# ATSAMG55J register map
Vendor: Microchip Technology; Series: SAMG55; File version: 0
CPU: CM4 r0p1, little endian, MPU, FPU, 4 interrupt priority bits
Registers are 32-bit, read-write, reset 0x0 unless marked. A register's access mark holds for its fields unless they carry their own. Offsets are from the block's base; [hi:lo] are bit positions; {n}, {i} and the like mark numbered series.

## RSTC — Reset Controller
Base 0x400E1400; register names take the prefix RSTC_
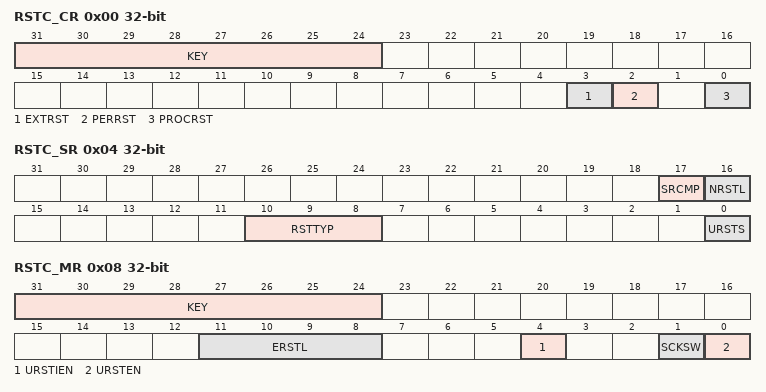
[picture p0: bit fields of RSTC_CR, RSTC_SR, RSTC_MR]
0x00 RSTC_CR wo — Control Register
  [31:24] KEY — System Reset Key
    165=PASSWD (Writing any other value in this field aborts the write operation.)
  [3] EXTRST — External Reset
  [2] PERRST — Peripheral Reset
  [0] PROCRST — Processor Reset
0x04 RSTC_SR ro — Status Register
  [17] SRCMP — Software Reset Command in Progress
  [16] NRSTL — NRST Pin Level
  [10:8] RSTTYP — Reset Type
    0=GENERAL_RST (First power-up reset); 1=BACKUP_RST (Return from Backup Mode); 2=WDT_RST (Watchdog fault occurred); 3=SOFT_RST (Processor reset required by the software); 4=USER_RST (NRST pin detected low); 7=SLCK_XTAL_RST (Slow Crystal Failure Detection fault occured)
  [0] URSTS — User Reset Status
0x08 RSTC_MR — Mode Register
  [31:24] KEY — Write Access Password
    165=PASSWD (Writing any other value in this field aborts the write operation.Always reads as 0.)
  [11:8] ERSTL — External Reset Length
  [4] URSTIEN — User Reset Interrupt Enable
  [1] SCKSW — Slow Clock Switching
  [0] URSTEN — User Reset Enable

## RTT — Real-time Timer
Base 0x400E1430; register names take the prefix RTT_
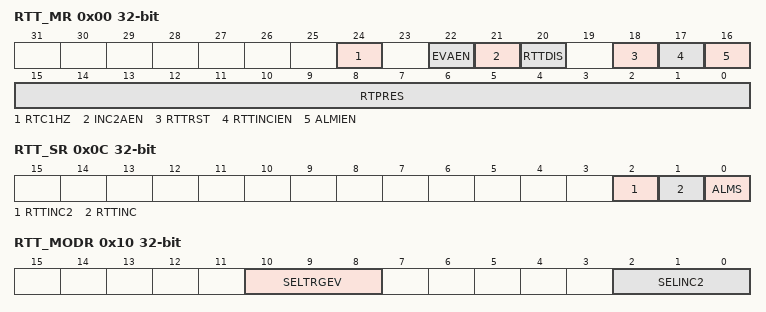
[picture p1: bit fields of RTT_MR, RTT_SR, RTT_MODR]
0x00 RTT_MR — Mode Register
  [24] RTC1HZ — Real-Time Clock 1Hz Clock Selection
  [22] EVAEN — Trigger Event Alarm Enable
  [21] INC2AEN — RTTINC2 Alarm Enable
  [20] RTTDIS — Real-time Timer Disable
  [18] RTTRST — Real-time Timer Restart
  [17] RTTINCIEN — Real-time Timer Increment Interrupt Enable
  [16] ALMIEN — Alarm Interrupt Enable
  [15:0] RTPRES — Real-time Timer Prescaler Value
0x04 RTT_AR — Alarm Register
  [31:0] ALMV — Alarm Value
0x08 RTT_VR ro — Value Register
  [31:0] CRTV — Current Real-time Value
0x0C RTT_SR ro — Status Register
  [2] RTTINC2 — Predefined Number of Prescaler Roll-over Status (cleared on read)
  [1] RTTINC — Prescaler Roll-over Status (cleared on read)
  [0] ALMS — Real-time Alarm Status (cleared on read)
0x10 RTT_MODR — Modulo Selection Register
  [10:8] SELTRGEV — Selection of the 32-bit Counter Modulo to generate the trigger event
    0=NO_EVENT (No event generated); 1=MOD2 (Event occurs when CRTV modulo 2 equals 0); 2=MOD4 (Event occurs when CRTV modulo 4 equals 0); 3=MOD8 (Event occurs when CRTV modulo 8 equals 0); 4=MOD16 (Event occurs when CRTV modulo 16 equals 0); 5=MOD32 (Event occurs when CRTV modulo 32 equals 0); 6=MOD64 (Event occurs when CRTV modulo 64 equals 0); 7=MOD128 (Event occurs when CRTV modulo 128 equals 0)
  [2:0] SELINC2 — Selection of the 32-bit Counter Modulo to generate RTTINC2 flag
    0=NO_RTTINC2 (The RTTINC2 flag never rises); 1=MOD64 (The RTTINC2 flag is set when CRTV modulo 64 equals 0); 2=MOD128 (The RTTINC2 flag is set when CRTV modulo 128 equals 0); 3=MOD256 (The RTTINC2 flag is set when CRTV modulo 256 equals 0); 4=MOD512 (The RTTINC2 flag is set when CRTV modulo 512 equals 0); 5=MOD1024 (The RTTINC2 flag is set when CRTV modulo 1024 equals 0.Example: If RTPRES=32 then RTTINC2 flag rises once per second if the slow clock is 32.768 kHz.); 6=MOD2048 (The RTTINC2 flag is set when CRTV modulo 2048 equals 0); 7=MOD4096 (The RTTINC2 flag is set when CRTV modulo 4096 equals 0)

## UDP — USB Device Port
Base 0x40044000; register names take the prefix UDP_
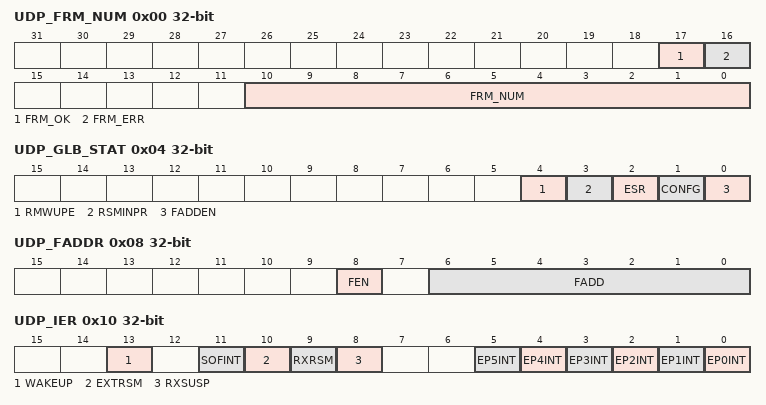
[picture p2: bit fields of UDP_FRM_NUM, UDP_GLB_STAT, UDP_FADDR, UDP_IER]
0x00 UDP_FRM_NUM ro — Frame Number Register
  [17] FRM_OK — Frame OK
  [16] FRM_ERR — Frame Error
  [10:0] FRM_NUM — Frame Number as Defined in the Packet Field Formats
0x04 UDP_GLB_STAT — Global State Register
  [4] RMWUPE — Remote Wakeup Enable
  [3] RSMINPR
  [2] ESR — Enable Send Resume
  [1] CONFG — Configured
  [0] FADDEN — Function Address Enable
0x08 UDP_FADDR — Function Address Register
  [8] FEN — Function Enable
  [6:0] FADD — Function Address Value
0x10 UDP_IER wo — Interrupt Enable Register
  [13] WAKEUP — Enable UDP Bus Wakeup Interrupt
  [11] SOFINT — Enable Start Of Frame Interrupt
  [10] EXTRSM
  [9] RXRSM — Enable UDP Resume Interrupt
  [8] RXSUSP — Enable UDP Suspend Interrupt
  [5] EP5INT — Enable Endpoint 5 Interrupt
  [4] EP4INT — Enable Endpoint 4 Interrupt
  [3] EP3INT — Enable Endpoint 3 Interrupt
  [2] EP2INT — Enable Endpoint 2Interrupt
  [1] EP1INT — Enable Endpoint 1 Interrupt
  [0] EP0INT — Enable Endpoint 0 Interrupt
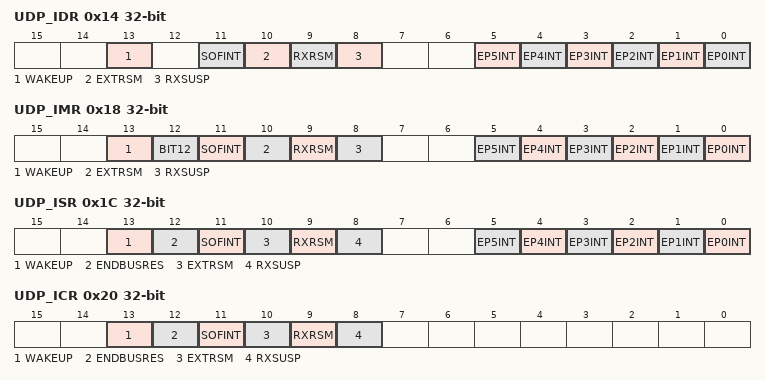
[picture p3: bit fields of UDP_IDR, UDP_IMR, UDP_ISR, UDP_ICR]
0x14 UDP_IDR wo — Interrupt Disable Register
  [13] WAKEUP — Disable USB Bus Interrupt
  [11] SOFINT — Disable Start Of Frame Interrupt
  [10] EXTRSM
  [9] RXRSM — Disable UDP Resume Interrupt
  [8] RXSUSP — Disable UDP Suspend Interrupt
  [n] EP{n}INT (n=0..5) — Disable Endpoint {n} Interrupt
0x18 UDP_IMR ro — Interrupt Mask Register
  [13] WAKEUP — USB Bus Wakeup Interrupt
  [12] BIT12 — UDP_IMR Bit 12
  [11] SOFINT — Mask Start Of Frame Interrupt
  [10] EXTRSM
  [9] RXRSM — Mask UDP Resume Interrupt.
  [8] RXSUSP — Mask UDP Suspend Interrupt
  [n] EP{n}INT (n=0..5) — Mask Endpoint {n} Interrupt
0x1C UDP_ISR ro — Interrupt Status Register
  [13] WAKEUP — UDP Resume Interrupt Status
  [12] ENDBUSRES — End of BUS Reset Interrupt Status
  [11] SOFINT — Start of Frame Interrupt Status
  [10] EXTRSM
  [9] RXRSM — UDP Resume Interrupt Status
  [8] RXSUSP — UDP Suspend Interrupt Status
  [n] EP{n}INT (n=0..5) — Endpoint {n} Interrupt Status
0x20 UDP_ICR wo — Interrupt Clear Register
  [13] WAKEUP — Clear Wakeup Interrupt
  [12] ENDBUSRES — Clear End of Bus Reset Interrupt
  [11] SOFINT — Clear Start Of Frame Interrupt
  [10] EXTRSM
  [9] RXRSM — Clear UDP Resume Interrupt
  [8] RXSUSP — Clear UDP Suspend Interrupt
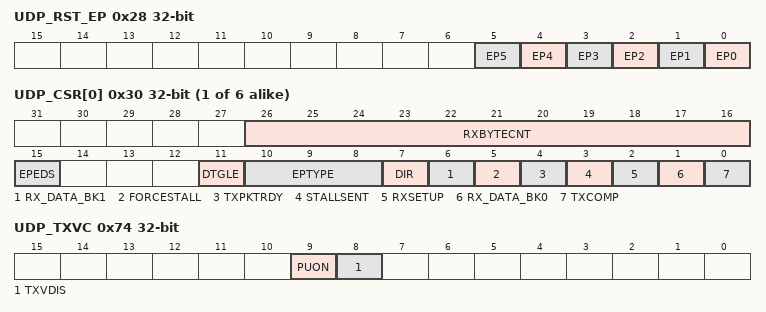
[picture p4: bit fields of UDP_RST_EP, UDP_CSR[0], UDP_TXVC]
0x28 UDP_RST_EP — Reset Endpoint Register
  [n] EP{n} (n=0..5) — Reset Endpoint {n}
{0x30+4i} UDP_CSR[{i}] (i=0..5) — Endpoint Control and Status Register 0
  [26:16] RXBYTECNT — Number of Bytes Available in the FIFO (Read-only)
  [15] EPEDS — Endpoint Enable Disable
  [11] DTGLE — Data Toggle (Read-only)
  [10:8] EPTYPE — Endpoint Type (Read/Write)
    0=CTRL (Control); 1=ISO_OUT (Isochronous OUT); 2=BULK_OUT; 3=INT_OUT (Interrupt OUT); 5=ISO_IN (Isochronous IN); 6=BULK_IN; 7=INT_IN (Interrupt IN)
  [7] DIR — Transfer Direction (only available for control endpoints) (Read/Write)
  [6] RX_DATA_BK1 — Receive Data Bank 1 (only used by endpoints with ping-pong attributes)
  [5] FORCESTALL — Force Stall (used by Control, Bulk and Isochronous Endpoints)
  [4] TXPKTRDY — Transmit Packet Ready
  [3] STALLSENT
  [2] RXSETUP — Received Setup
  [1] RX_DATA_BK0 — Receive Data Bank 0
  [0] TXCOMP — Generates an IN Packet with Data Previously Written in the DPR
{0x50+4i} UDP_FDR[{i}] (i=0..5) — Endpoint FIFO Data Register 0
  [7:0] FIFO_DATA — FIFO Data Value
0x74 UDP_TXVC — Transceiver Control Register
  [9] PUON — Pull-up On
  [8] TXVDIS — Transceiver Disable
